# hazard4eduMinimal register map
Vendor: riscV_edu_platform; File version: 1.0
Hazard3 RV32IM with JTAG debug, 64 KiB SRAM at 0x00000000 and a 16550 compatible UART at 0x00010000, on a shared Wishbone bus (GECKO5Education, ECP5 LFE5U-85)
Registers are 8-bit, read-write, reset 0x0 unless marked. A register's access mark holds for its fields unless they carry their own. Offsets are from the block's base; lines under a group give offsets from that group; [hi:lo] are bit positions; {n}, {i} and the like mark numbered series; 'fields as' and 'values as' point back to an identical list; <NAME> marks a mode.

## Memory map
0x00010000 UART0 size 0x8 — 16550 compatible UART (hdl/modules/uart): byte registers, 16 byte FIFOs that are always enabled, baud clock 50 MHz (divisor = 50 MHz / (16 * baud))

## Interrupts
0 UART0 — UART interrupt (not connected to the CPU in hazard4eduMinimal)

## UART0 — 16550 compatible UART (hdl/modules/uart): byte registers, 16 byte FIFOs that are always enabled, baud clock 50 MHz (divisor = 50 MHz / (16 * baud))
Base 0x00010000
0x00 RBR ro read-modifies — Receiver buffer (LCR.DLAB = 0). Reading takes the byte out of the receive FIFO, also when DLAB = 1.
  [7:0] DATA — Received byte
0x00 THR wo (alternate view of RBR) — Transmitter holding register (LCR.DLAB = 0): writing puts a byte into the transmit FIFO
  [7:0] DATA — Byte to send
0x00 DLL read-modifies (alternate view of RBR) — Divisor latch, low byte (LCR.DLAB = 1). Shows the receiver buffer while DLAB = 0.
  [7:0] DLL — Divisor bits 7:0
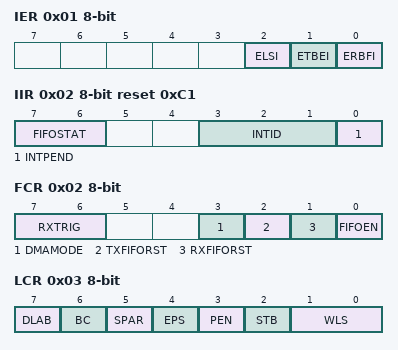
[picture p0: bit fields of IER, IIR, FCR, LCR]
0x01 IER — Interrupt enable (LCR.DLAB = 0). Only ERBFI and ETBEI are stored.
  [2] ELSI ro — Receiver line status interrupt enable (not stored by this UART, reads 0)
  [1] ETBEI — Transmitter holding register empty interrupt enable
  [0] ERBFI — Received data available interrupt enable
0x01 DLM (alternate view of IER) — Divisor latch, high byte (LCR.DLAB = 1). Shows IER while DLAB = 0.
  [7:0] DLM — Divisor bits 15:8
0x02 IIR ro reset 0xC1 read-modifies — Interrupt identification. Reading clears the transmitter holding register empty interrupt.
  [7:6] FIFOSTAT — FIFOs enabled (always 0b11)
  [3:1] INTID — Interrupt identification, highest priority first
    3=LINESTATUS (Receiver line status); 2=RXDATA (Received data available); 1=THRE (Transmitter holding register empty); 0=MODEM (Modem status (not implemented))
  [0] INTPEND — 0 = an interrupt is pending, 1 = none pending
0x02 FCR wo (alternate view of IIR) — FIFO control (write only)
  [7:6] RXTRIG — Receiver FIFO trigger level for the received data interrupt
    0=1BYTE; 1=4BYTES; 2=8BYTES; 3=14BYTES
  [3] DMAMODE — DMA mode select (no effect)
  [2] TXFIFORST — Transmitter FIFO reset (self-clearing)
  [1] RXFIFORST — Receiver FIFO reset (self-clearing)
  [0] FIFOEN — FIFO enable (FIFOs are always on, no effect)
0x03 LCR — Line control
  [7] DLAB — Divisor latch access: offsets 0 and 1 address DLL and DLM
  [6] BC — Break control: hold TxD low
  [5] SPAR — Stick parity (with PEN: parity bit = !EPS)
  [4] EPS — Even parity select
  [3] PEN — Parity enable
  [2] STB — Stop bits: 0 = 1, 1 = 2 (1.5 for 5-bit words)
  [1:0] WLS — Word length
    {v}={v+5}BIT ({v+5} data bits) (v=0..3)
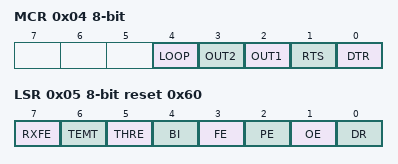
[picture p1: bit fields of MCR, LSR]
0x04 MCR — Modem control. Only LOOP is implemented.
  [4] LOOP — Loopback: TxD held high, the transmitter feeds the receiver
  [3] OUT2 ro — Output 2 (not implemented)
  [2] OUT1 ro — Output 1 (not implemented)
  [1] RTS ro — Request to send (not implemented)
  [0] DTR ro — Data terminal ready (not implemented)
0x05 LSR ro reset 0x60 read-modifies — Line status. Reading clears OE, PE, FE, BI and the line status interrupt.
  [7] RXFE — Error in the receive FIFO
  [6] TEMT — Transmitter empty: FIFO and shift register idle
  [5] THRE — Transmitter holding register (FIFO) empty
  [4] BI — Break interrupt
  [3] FE — Framing error
  [2] PE — Parity error
  [1] OE — Overrun error
  [0] DR — Data ready: the receive FIFO holds at least one byte
0x06 MSR ro — Modem status (not implemented, reads 0)
0x07 SCR — Scratch register: 8 bits for free use, no effect on the UART
